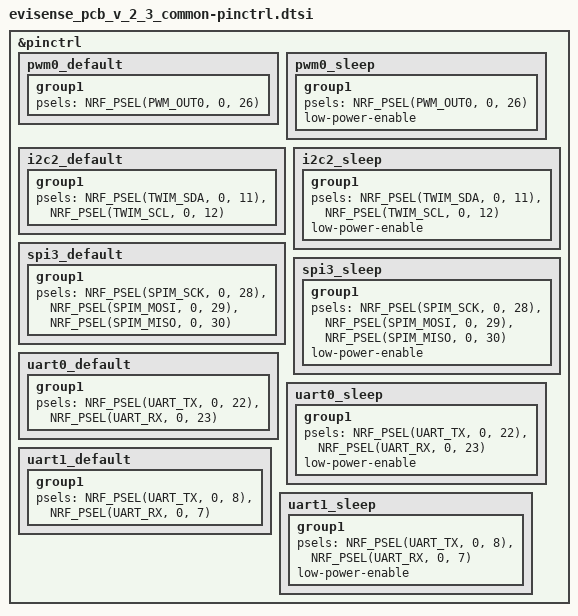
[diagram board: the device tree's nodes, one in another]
&pinctrl {
	pwm0_default: pwm0_default {
		group1 {
			psels = <NRF_PSEL(PWM_OUT0, 0, 26)>;
		};
	};

	pwm0_sleep: pwm0_sleep {
		group1 {
			psels = <NRF_PSEL(PWM_OUT0, 0, 26)>;
			low-power-enable;
		};
	};

	i2c2_default: i2c2_default {
		group1 {
			psels = <NRF_PSEL(TWIM_SDA, 0, 11)>,
				<NRF_PSEL(TWIM_SCL, 0, 12)>;
		};
	};

	i2c2_sleep: i2c2_sleep {
		group1 {
			psels = <NRF_PSEL(TWIM_SDA, 0, 11)>,
				<NRF_PSEL(TWIM_SCL, 0, 12)>;
			low-power-enable;
		};
	};

	spi3_default: spi3_default {
		group1 {
			psels = <NRF_PSEL(SPIM_SCK, 0, 28)>,
				<NRF_PSEL(SPIM_MOSI, 0, 29)>,
				<NRF_PSEL(SPIM_MISO, 0, 30)>;
		};
	};

	spi3_sleep: spi3_sleep {
		group1 {
			psels = <NRF_PSEL(SPIM_SCK, 0, 28)>,
				<NRF_PSEL(SPIM_MOSI, 0, 29)>,
				<NRF_PSEL(SPIM_MISO, 0, 30)>;
			low-power-enable;
		};
	};

	uart0_default: uart0_default {
		group1 {
			psels = <NRF_PSEL(UART_TX, 0, 22)>,
				<NRF_PSEL(UART_RX, 0, 23)>;
		};
	};

	uart0_sleep: uart0_sleep {
		group1 {
			psels = <NRF_PSEL(UART_TX, 0, 22)>,
				<NRF_PSEL(UART_RX, 0, 23)>;
			low-power-enable;
		};
	};

	uart1_default: uart1_default {
		group1 {
			psels = <NRF_PSEL(UART_TX, 0, 8)>,
				<NRF_PSEL(UART_RX, 0, 7)>;
		};
	};

	uart1_sleep: uart1_sleep {
		group1 {
			psels = <NRF_PSEL(UART_TX, 0, 8)>,
				<NRF_PSEL(UART_RX, 0, 7)>;
			low-power-enable;
		};
	};
};
